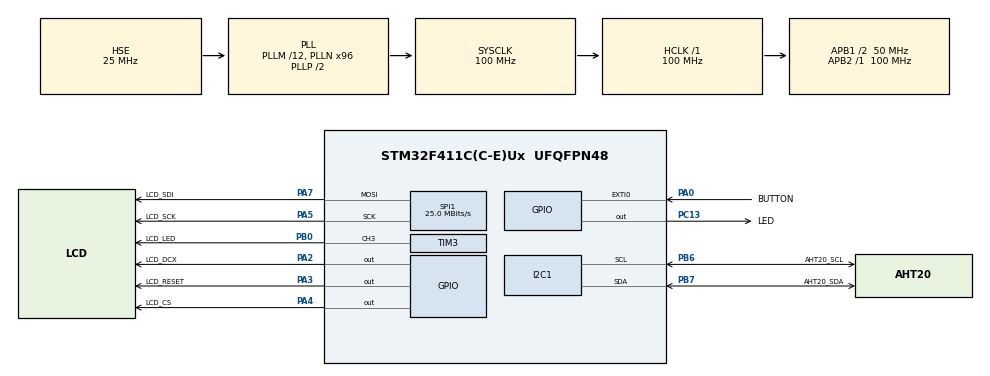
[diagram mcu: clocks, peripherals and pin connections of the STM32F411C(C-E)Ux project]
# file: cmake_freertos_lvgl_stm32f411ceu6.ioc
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Dma.Request0=SPI1_TX
Dma.SPI1_TX.0.Direction=DMA_MEMORY_TO_PERIPH
Dma.SPI1_TX.0.FIFOMode=DMA_FIFOMODE_DISABLE
Dma.SPI1_TX.0.Instance=DMA2_Stream2
Dma.SPI1_TX.0.MemDataAlignment=DMA_MDATAALIGN_HALFWORD
Dma.SPI1_TX.0.MemInc=DMA_MINC_ENABLE
Dma.SPI1_TX.0.Mode=DMA_NORMAL
Dma.SPI1_TX.0.PeriphDataAlignment=DMA_PDATAALIGN_HALFWORD
Dma.SPI1_TX.0.PeriphInc=DMA_PINC_DISABLE
Dma.SPI1_TX.0.Priority=DMA_PRIORITY_MEDIUM
FREERTOS.Queues01=buttonQueue,16,uint16_t,0,Dynamic,NULL,NULL;aht20Queue,16,AHT20_Data_t,0,Dynamic,NULL,NULL
FREERTOS.Tasks01=defaultTask,0,128,StartDefaultTask,Default,NULL,Dynamic,NULL,NULL;ledTask,-3,128,StartLedTask,Default,NULL,Dynamic,NULL,NULL;aht20Task,-3,128,StartAht20Task,As weak,aht20QueueHandle,Dynamic,NULL,NULL;displayTask,-3,1024,StartDisplayTask,As weak,aht20QueueHandle,Dynamic,NULL,NULL
FREERTOS.configUSE_NEWLIB_REENTRANT=1
Mcu.Family=STM32F4
Mcu.Name=STM32F411C(C-E)Ux
Mcu.Package=UFQFPN48
NVIC.DMA2_Stream2_IRQn=true\:5\:0\:false\:false\:true\:true\:false\:true\:true
NVIC.EXTI0_IRQn=true\:5\:0\:false\:false\:true\:true\:true\:true\:true
NVIC.PriorityGroup=NVIC_PRIORITYGROUP_4
NVIC.SPI1_IRQn=true\:5\:0\:false\:false\:true\:true\:true\:true\:true
NVIC.TIM2_IRQn=true\:15\:0\:false\:false\:true\:false\:false\:true\:true
NVIC.TimeBase=TIM2_IRQn
NVIC.TimeBaseIP=TIM2
PA0-WKUP.GPIO_Label=BUTTON
PA0-WKUP.GPIO_ModeDefaultEXTI=GPIO_MODE_IT_FALLING
PA0-WKUP.GPIO_PuPd=GPIO_PULLUP
PA0-WKUP.Signal=GPXTI0
PA13.Mode=Serial_Wire
PA13.Signal=SYS_JTMS-SWDIO
PA14.Mode=Serial_Wire
PA14.Signal=SYS_JTCK-SWCLK
PA2.GPIO_Label=LCD_DCX
PA2.GPIO_Speed=GPIO_SPEED_FREQ_VERY_HIGH
PA2.PinState=GPIO_PIN_SET
PA2.Signal=GPIO_Output
PA3.GPIO_Label=LCD_RESET
PA3.GPIO_PuPd=GPIO_PULLUP
PA3.PinState=GPIO_PIN_SET
PA3.Signal=GPIO_Output
PA4.GPIO_Label=LCD_CS
PA4.GPIO_Speed=GPIO_SPEED_FREQ_VERY_HIGH
PA4.Signal=GPIO_Output
PA5.GPIO_Label=LCD_SCK
PA5.GPIO_PuPd=GPIO_PULLDOWN
PA5.Mode=TX_Only_Simplex_Unidirect_Master
PA5.Signal=SPI1_SCK
PA7.GPIO_Label=LCD_SDI
PA7.GPIO_PuPd=GPIO_PULLUP
PA7.Mode=TX_Only_Simplex_Unidirect_Master
PA7.Signal=SPI1_MOSI
PB0.GPIO_Label=LCD_LED
PB0.Signal=S_TIM3_CH3
PB6.GPIO_Label=AHT20_SCL
PB6.Mode=I2C
PB6.Signal=I2C1_SCL
PB7.GPIO_Label=AHT20_SDA
PB7.Mode=I2C
PB7.Signal=I2C1_SDA
PC13-ANTI_TAMP.GPIO_Label=LED
PC13-ANTI_TAMP.Signal=GPIO_Output
PH0\ -\ OSC_IN.Mode=HSE-External-Oscillator
PH0\ -\ OSC_IN.Signal=RCC_OSC_IN
PH1\ -\ OSC_OUT.Mode=HSE-External-Oscillator
PH1\ -\ OSC_OUT.Signal=RCC_OSC_OUT
ProjectManager.HeapSize=0x200
ProjectManager.StackSize=0x400
ProjectManager.TargetToolchain=CMake
RCC.48MHZClocksFreq_Value=50000000
RCC.AHBFreq_Value=100000000
RCC.APB1CLKDivider=RCC_HCLK_DIV2
RCC.APB1Freq_Value=50000000
RCC.APB1TimFreq_Value=100000000
RCC.APB2Freq_Value=100000000
RCC.APB2TimFreq_Value=100000000
RCC.CortexFreq_Value=100000000
RCC.HCLKFreq_Value=100000000
RCC.HSE_VALUE=25000000
RCC.HSI_VALUE=16000000
RCC.LSE_VALUE=32768
RCC.PLLM=12
RCC.PLLN=96
RCC.PLLSourceVirtual=RCC_PLLSOURCE_HSE
RCC.SYSCLKFreq_VALUE=100000000
RCC.SYSCLKSource=RCC_SYSCLKSOURCE_PLLCLK
RCC.VCOOutputFreq_Value=200000000
SH.S_TIM3_CH3.0=TIM3_CH3,PWM Generation3 CH3
SPI1.BaudRatePrescaler=SPI_BAUDRATEPRESCALER_4
SPI1.CalculateBaudRate=25.0 MBits/s
SPI1.Direction=SPI_DIRECTION_2LINES
SPI1.Mode=SPI_MODE_MASTER
SPI1.VirtualType=VM_MASTER
TIM3.Channel-PWM\ Generation3\ CH3=TIM_CHANNEL_3
TIM3.Period=100
TIM3.Prescaler=10000
VP_FREERTOS_VS_CMSIS_V1.Mode=CMSIS_V1
VP_SYS_VS_tim2.Mode=TIM2
VP_TIM3_VS_ClockSourceINT.Mode=Internal
board=custom

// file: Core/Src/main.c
/* USER CODE BEGIN Header */
/**
  ******************************************************************************
  * @file           : main.c
  * @brief          : Main program body
  ******************************************************************************
  * @attention
  *
  * Copyright (c) 2025 STMicroelectronics.
  * All rights reserved.
  *
  * This software is licensed under terms that can be found in the LICENSE file
  * in the root directory of this software component.
  * If no LICENSE file comes with this software, it is provided AS-IS.
  *
  ******************************************************************************
  */
/* USER CODE END Header */
#include "main.h"
#include "cmsis_os.h"
#include "dma.h"
#include "i2c.h"
#include "spi.h"
#include "tim.h"
#include "gpio.h"

void SystemClock_Config(void);
void MX_FREERTOS_Init(void);

int main(void)
{

  /* MCU Configuration--------------------------------------------------------*/

  /* Reset of all peripherals, Initializes the Flash interface and the Systick. */
  HAL_Init();

  /* Configure the system clock */
  SystemClock_Config();

  /* Initialize all configured peripherals */
  MX_GPIO_Init();
  MX_DMA_Init();
  MX_SPI1_Init();
  MX_TIM3_Init();
  MX_I2C1_Init();

  /* Call init function for freertos objects (in cmsis_os2.c) */
  MX_FREERTOS_Init();

  /* Start scheduler */
  osKernelStart();

  /* We should never get here as control is now taken by the scheduler */

  /* Infinite loop */
  while (1)
  {

  }
}

void SystemClock_Config(void)
{
  RCC_OscInitTypeDef RCC_OscInitStruct = {0};
  RCC_ClkInitTypeDef RCC_ClkInitStruct = {0};

  /** Configure the main internal regulator output voltage
  */
  __HAL_RCC_PWR_CLK_ENABLE();
  __HAL_PWR_VOLTAGESCALING_CONFIG(PWR_REGULATOR_VOLTAGE_SCALE1);

  /** Initializes the RCC Oscillators according to the specified parameters
  * in the RCC_OscInitTypeDef structure.
  */
  RCC_OscInitStruct.OscillatorType = RCC_OSCILLATORTYPE_HSE;
  RCC_OscInitStruct.HSEState = RCC_HSE_ON;
  RCC_OscInitStruct.PLL.PLLState = RCC_PLL_ON;
  RCC_OscInitStruct.PLL.PLLSource = RCC_PLLSOURCE_HSE;
  RCC_OscInitStruct.PLL.PLLM = 12;
  RCC_OscInitStruct.PLL.PLLN = 96;
  RCC_OscInitStruct.PLL.PLLP = RCC_PLLP_DIV2;
  RCC_OscInitStruct.PLL.PLLQ = 4;
  if (HAL_RCC_OscConfig(&RCC_OscInitStruct) != HAL_OK)
  {
    Error_Handler();
  }

  /** Initializes the CPU, AHB and APB buses clocks
  */
  RCC_ClkInitStruct.ClockType = RCC_CLOCKTYPE_HCLK|RCC_CLOCKTYPE_SYSCLK
                              |RCC_CLOCKTYPE_PCLK1|RCC_CLOCKTYPE_PCLK2;
  RCC_ClkInitStruct.SYSCLKSource = RCC_SYSCLKSOURCE_PLLCLK;
  RCC_ClkInitStruct.AHBCLKDivider = RCC_SYSCLK_DIV1;
  RCC_ClkInitStruct.APB1CLKDivider = RCC_HCLK_DIV2;
  RCC_ClkInitStruct.APB2CLKDivider = RCC_HCLK_DIV1;

  if (HAL_RCC_ClockConfig(&RCC_ClkInitStruct, FLASH_LATENCY_3) != HAL_OK)
  {
    Error_Handler();
  }
}

void HAL_TIM_PeriodElapsedCallback(TIM_HandleTypeDef *htim)
{
  if (htim->Instance == TIM2)
  {
    HAL_IncTick();
  }
}

void Error_Handler(void)
{
  __disable_irq();
  while (1)
  {
  }
}

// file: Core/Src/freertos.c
/* USER CODE BEGIN Header */
/**
  ******************************************************************************
  * File Name          : freertos.c
  * Description        : Code for freertos applications
  ******************************************************************************
  * @attention
  *
  * Copyright (c) 2025 STMicroelectronics.
  * All rights reserved.
  *
  * This software is licensed under terms that can be found in the LICENSE file
  * in the root directory of this software component.
  * If no LICENSE file comes with this software, it is provided AS-IS.
  *
  ******************************************************************************
  */
/* USER CODE END Header */

#include "FreeRTOS.h"
#include "task.h"
#include "main.h"
#include "cmsis_os.h"

/* USER CODE BEGIN Includes */
#include "common.h"
/* USER CODE END Includes */

osThreadId defaultTaskHandle;
osThreadId ledTaskHandle;
osThreadId aht20TaskHandle;
osThreadId displayTaskHandle;
osMessageQId buttonQueueHandle;
osMessageQId aht20QueueHandle;

void StartDefaultTask(void const * argument);
void StartLedTask(void const * argument);
void StartAht20Task(void const * argument);
void StartDisplayTask(void const * argument);

void MX_FREERTOS_Init(void); /* (MISRA C 2004 rule 8.1) */

/* GetIdleTaskMemory prototype (linked to static allocation support) */
void vApplicationGetIdleTaskMemory( StaticTask_t **ppxIdleTaskTCBBuffer, StackType_t **ppxIdleTaskStackBuffer, uint32_t *pulIdleTaskStackSize );

/* USER CODE BEGIN GET_IDLE_TASK_MEMORY */
static StaticTask_t xIdleTaskTCBBuffer;
static StackType_t xIdleStack[configMINIMAL_STACK_SIZE];

void vApplicationGetIdleTaskMemory( StaticTask_t **ppxIdleTaskTCBBuffer, StackType_t **ppxIdleTaskStackBuffer, uint32_t *pulIdleTaskStackSize )
{
  *ppxIdleTaskTCBBuffer = &xIdleTaskTCBBuffer;
  *ppxIdleTaskStackBuffer = &xIdleStack[0];
  *pulIdleTaskStackSize = configMINIMAL_STACK_SIZE;
  /* place for user code */
}
/* USER CODE END GET_IDLE_TASK_MEMORY */

void MX_FREERTOS_Init(void) {

  /* Create the queue(s) */
  /* definition and creation of buttonQueue */
  osMessageQDef(buttonQueue, 16, uint16_t);
  buttonQueueHandle = osMessageCreate(osMessageQ(buttonQueue), NULL);

  /* definition and creation of aht20Queue */
  osMessageQDef(aht20Queue, 16, AHT20_Data_t);
  aht20QueueHandle = osMessageCreate(osMessageQ(aht20Queue), NULL);

  /* Create the thread(s) */
  /* definition and creation of defaultTask */
  osThreadDef(defaultTask, StartDefaultTask, osPriorityNormal, 0, 128);
  defaultTaskHandle = osThreadCreate(osThread(defaultTask), NULL);

  /* definition and creation of ledTask */
  osThreadDef(ledTask, StartLedTask, osPriorityIdle, 0, 128);
  ledTaskHandle = osThreadCreate(osThread(ledTask), (void*) buttonQueueHandle);

  /* definition and creation of aht20Task */
  osThreadDef(aht20Task, StartAht20Task, osPriorityIdle, 0, 128);
  aht20TaskHandle = osThreadCreate(osThread(aht20Task), (void*) aht20QueueHandle);

  /* definition and creation of displayTask */
  osThreadDef(displayTask, StartDisplayTask, osPriorityIdle, 0, 1024);
  displayTaskHandle = osThreadCreate(osThread(displayTask), (void*) aht20QueueHandle);

}

void StartDefaultTask(void const * argument)
{
  for(;;)
  {
    osDelay(1);
  }
}

__weak void StartLedTask(void const * argument)
{
  for(;;)
  {
    osDelay(1);
  }
}

__weak void StartAht20Task(void const * argument)
{
  for(;;)
  {
    osDelay(1);
  }
}

__weak void StartDisplayTask(void const * argument)
{
  for(;;)
  {
    osDelay(1);
  }
}

/* USER CODE BEGIN Application */
void HAL_GPIO_EXTI_Callback(uint16_t GPIO_Pin)
{
  currentTime = HAL_GetTick();
  if (GPIO_Pin == BUTTON_Pin && (currentTime - previousTime > 5)) {
    if (value < 500) {
      value = 1000;
    } else {
      value = 100;
    }
    xQueueSendToBackFromISR(buttonQueueHandle, &value, 0);
    previousTime = currentTime;
  } else {
    __NOP();
  }
}
/* USER CODE END Application */
